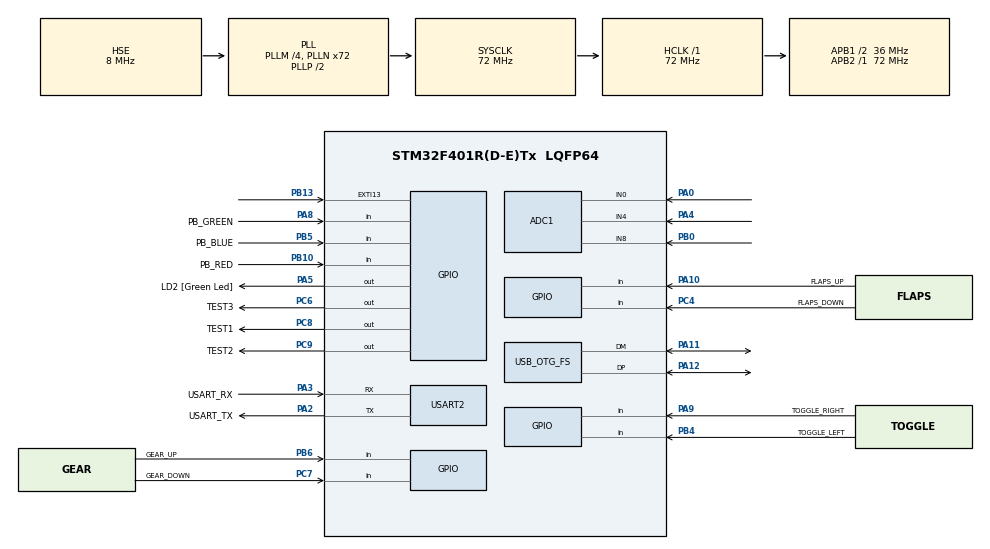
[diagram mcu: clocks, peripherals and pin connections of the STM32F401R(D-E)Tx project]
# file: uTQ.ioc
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ADC1.Channel-0\#ChannelRegularConversion=ADC_CHANNEL_0
ADC1.Channel-1\#ChannelRegularConversion=ADC_CHANNEL_8
ADC1.Channel-2\#ChannelRegularConversion=ADC_CHANNEL_4
ADC1.ClockPrescaler=ADC_CLOCK_SYNC_PCLK_DIV4
ADC1.EOCSelection=ADC_EOC_SEQ_CONV
ADC1.NbrOfConversion=3
ADC1.NbrOfConversionFlag=1
ADC1.Rank-0\#ChannelRegularConversion=1
ADC1.Rank-1\#ChannelRegularConversion=2
ADC1.Rank-2\#ChannelRegularConversion=3
ADC1.SamplingTime-0\#ChannelRegularConversion=ADC_SAMPLETIME_480CYCLES
ADC1.SamplingTime-1\#ChannelRegularConversion=ADC_SAMPLETIME_480CYCLES
ADC1.SamplingTime-2\#ChannelRegularConversion=ADC_SAMPLETIME_480CYCLES
ADC1.ScanConvMode=ENABLE
ADC1.master=1
Dma.ADC1.0.Direction=DMA_PERIPH_TO_MEMORY
Dma.ADC1.0.FIFOMode=DMA_FIFOMODE_DISABLE
Dma.ADC1.0.Instance=DMA2_Stream0
Dma.ADC1.0.MemDataAlignment=DMA_MDATAALIGN_HALFWORD
Dma.ADC1.0.MemInc=DMA_MINC_ENABLE
Dma.ADC1.0.Mode=DMA_NORMAL
Dma.ADC1.0.PeriphDataAlignment=DMA_PDATAALIGN_HALFWORD
Dma.ADC1.0.PeriphInc=DMA_PINC_DISABLE
Dma.ADC1.0.Priority=DMA_PRIORITY_LOW
Dma.Request0=ADC1
IWDG.Prescaler=IWDG_PRESCALER_16
IWDG.Reload=1999
Mcu.Family=STM32F4
Mcu.Name=STM32F401R(D-E)Tx
Mcu.Package=LQFP64
Mcu.UserConstants=CUSTOM_HID_EPIN_SIZE,64;CUSTOM_HID_EPOUT_SIZE,64
NVIC.DMA2_Stream0_IRQn=true\:10\:0\:true\:false\:true\:false\:true\:true
NVIC.OTG_FS_IRQn=true\:0\:0\:false\:false\:true\:false\:true\:true
NVIC.PriorityGroup=NVIC_PRIORITYGROUP_4
PA0-WKUP.Signal=ADCx_IN0
PA10.GPIO_Label=FLAPS_UP
PA10.GPIO_PuPd=GPIO_PULLUP
PA10.Signal=GPIO_Input
PA11.Mode=Device_Only
PA11.Signal=USB_OTG_FS_DM
PA12.Mode=Device_Only
PA12.Signal=USB_OTG_FS_DP
PA13.GPIO_Label=TMS
PA13.Mode=Serial_Wire
PA13.Signal=SYS_JTMS-SWDIO
PA14.GPIO_Label=TCK
PA14.Mode=Serial_Wire
PA14.Signal=SYS_JTCK-SWCLK
PA2.GPIO_Label=USART_TX
PA2.GPIO_Mode=GPIO_MODE_AF_PP
PA2.GPIO_PuPd=GPIO_NOPULL
PA2.GPIO_Speed=GPIO_SPEED_FREQ_LOW
PA2.Mode=Asynchronous
PA2.Signal=USART2_TX
PA3.GPIO_Label=USART_RX
PA3.GPIO_Mode=GPIO_MODE_AF_PP
PA3.GPIO_PuPd=GPIO_NOPULL
PA3.GPIO_Speed=GPIO_SPEED_FREQ_LOW
PA3.Mode=Asynchronous
PA3.Signal=USART2_RX
PA4.Signal=ADCx_IN4
PA5.GPIO_Label=LD2 [Green Led]
PA5.GPIO_Mode=GPIO_MODE_OUTPUT_PP
PA5.GPIO_PuPd=GPIO_NOPULL
PA5.GPIO_Speed=GPIO_SPEED_FREQ_LOW
PA5.Signal=GPIO_Output
PA8.GPIO_Label=PB_GREEN
PA8.GPIO_PuPd=GPIO_PULLUP
PA8.Signal=GPIO_Input
PA9.GPIO_Label=TOGGLE_RIGHT
PA9.GPIO_PuPd=GPIO_PULLUP
PA9.Signal=GPIO_Input
PB0.Signal=ADCx_IN8
PB10.GPIO_Label=PB_RED
PB10.GPIO_PuPd=GPIO_PULLUP
PB10.Signal=GPIO_Input
PB13.Signal=GPXTI13
PB3.GPIO_Label=SWO
PB3.Signal=SYS_JTDO-SWO
PB4.GPIO_Label=TOGGLE_LEFT
PB4.GPIO_PuPd=GPIO_PULLUP
PB4.Signal=GPIO_Input
PB5.GPIO_Label=PB_BLUE
PB5.GPIO_PuPd=GPIO_PULLUP
PB5.Signal=GPIO_Input
PB6.GPIO_Label=GEAR_UP
PB6.GPIO_PuPd=GPIO_PULLUP
PB6.Signal=GPIO_Input
PC14-OSC32_IN.Mode=LSE-External-Oscillator
PC14-OSC32_IN.Signal=RCC_OSC32_IN
PC15-OSC32_OUT.Mode=LSE-External-Oscillator
PC15-OSC32_OUT.Signal=RCC_OSC32_OUT
PC4.GPIO_Label=FLAPS_DOWN
PC4.GPIO_PuPd=GPIO_PULLUP
PC4.Signal=GPIO_Input
PC6.GPIO_Label=TEST3
PC6.Signal=GPIO_Output
PC7.GPIO_Label=GEAR_DOWN
PC7.GPIO_PuPd=GPIO_PULLUP
PC7.Signal=GPIO_Input
PC8.GPIO_Label=TEST1
PC8.Signal=GPIO_Output
PC9.GPIO_Label=TEST2
PC9.Signal=GPIO_Output
PH0\ -\ OSC_IN.Mode=HSE-External-Clock-Source
PH0\ -\ OSC_IN.Signal=RCC_OSC_IN
PH1\ -\ OSC_OUT.Mode=HSE-External-Clock-Source
PH1\ -\ OSC_OUT.Signal=RCC_OSC_OUT
ProjectManager.HeapSize=0x400
ProjectManager.StackSize=0x800
ProjectManager.TargetToolchain=CMake
RCC.48MHZClocksFreq_Value=48000000
RCC.AHBFreq_Value=72000000
RCC.APB1CLKDivider=RCC_HCLK_DIV2
RCC.APB1Freq_Value=36000000
RCC.APB1TimFreq_Value=72000000
RCC.APB2Freq_Value=72000000
RCC.APB2TimFreq_Value=72000000
RCC.CortexFreq_Value=72000000
RCC.HCLKFreq_Value=72000000
RCC.HSE_VALUE=8000000
RCC.HSI_VALUE=16000000
RCC.PLLM=4
RCC.PLLN=72
RCC.PLLQ=3
RCC.SYSCLKFreq_VALUE=72000000
RCC.SYSCLKSource=RCC_SYSCLKSOURCE_PLLCLK
RCC.VCOOutputFreq_Value=144000000
SH.ADCx_IN0.0=ADC1_IN0,IN0
SH.ADCx_IN4.0=ADC1_IN4,IN4
SH.ADCx_IN8.0=ADC1_IN8,IN8
TIM5.Prescaler=71
USART2.VirtualMode=VM_ASYNC
USB_DEVICE.CLASS_NAME_FS=CUSTOM_HID
USB_DEVICE.MANUFACTURER_STRING-CUSTOM_HID_FS=C2030
USB_DEVICE.PID_CUSTOMHID_FS=0x5715
USB_DEVICE.PRODUCT_STRING_CUSTOMHID_FS=micro TQ
USB_DEVICE.USBD_CUSTOMHID_OUTREPORT_BUF_SIZE-CUSTOM_HID_FS=64
USB_DEVICE.USBD_CUSTOM_HID_REPORT_DESC_SIZE-CUSTOM_HID_FS=96
USB_DEVICE.VID-CUSTOM_HID_FS=0x0483
USB_DEVICE.VirtualMode-CUSTOM_HID_FS=CustomHid
USB_DEVICE.VirtualModeFS=Custom_Hid_FS
USB_OTG_FS.VirtualMode=Device_Only
VP_IWDG_VS_IWDG.Mode=IWDG_Activate
VP_TIM5_VS_ClockSourceINT.Mode=Internal
VP_USB_DEVICE_VS_USB_DEVICE_CUSTOM_HID_FS.Mode=CUSTOM_HID_FS
board=NUCLEO-F401RE

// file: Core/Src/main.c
/* USER CODE BEGIN Header */
/**
  ******************************************************************************
  * @file           : main.c
  * @brief          : Main program body
  ******************************************************************************
  * @attention
  *
  * Copyright (c) 2022 STMicroelectronics.
  * All rights reserved.
  *
  * This software is licensed under terms that can be found in the LICENSE file
  * in the root directory of this software component.
  * If no LICENSE file comes with this software, it is provided AS-IS.
  *
  ******************************************************************************
  */
/* USER CODE END Header */
#include "main.h"
#include "usb_device.h"

/* USER CODE BEGIN Includes */
#include "main_loop_api.h"
#include "stdio_redirection.h"
/* USER CODE END Includes */

ADC_HandleTypeDef hadc1;
DMA_HandleTypeDef hdma_adc1;

IWDG_HandleTypeDef hiwdg;

TIM_HandleTypeDef htim5;

UART_HandleTypeDef huart2;

void SystemClock_Config(void);
static void MX_GPIO_Init(void);
static void MX_DMA_Init(void);
static void MX_USART2_UART_Init(void);
static void MX_TIM5_Init(void);
static void MX_ADC1_Init(void);
static void MX_IWDG_Init(void);

int main(void)
{

  /* USER CODE BEGIN 1 */

    pTimerHtim = &htim5;    /*htim5 used by Timer class*/
    pHadc = &hadc1;         /*pointer to hadc1, which will be used in main loop*/
    pIwdg = &hiwdg;         /* pointer to main loop watchdog */
  /* USER CODE END 1 */

  /* MCU Configuration--------------------------------------------------------*/

  /* Reset of all peripherals, Initializes the Flash interface and the Systick. */
  HAL_Init();

  /* Configure the system clock */
  SystemClock_Config();

  /* Initialize all configured peripherals */
  MX_GPIO_Init();
  MX_DMA_Init();
  MX_USART2_UART_Init();
  MX_TIM5_Init();
  MX_USB_DEVICE_Init();
  MX_ADC1_Init();
  MX_IWDG_Init();
  /* USER CODE BEGIN 2 */
  redirectStdio(&huart2);     /*redirect stdio to console UART*/
  /* USER CODE END 2 */

  /* Infinite loop */
  /* USER CODE BEGIN WHILE */
  mainLoop();   /*it never returns from this function*/

  while (1)
  {
    /* USER CODE END WHILE */

  }
}

void SystemClock_Config(void)
{
  RCC_OscInitTypeDef RCC_OscInitStruct = {0};
  RCC_ClkInitTypeDef RCC_ClkInitStruct = {0};

  /** Configure the main internal regulator output voltage
  */
  __HAL_RCC_PWR_CLK_ENABLE();
  __HAL_PWR_VOLTAGESCALING_CONFIG(PWR_REGULATOR_VOLTAGE_SCALE2);

  /** Initializes the RCC Oscillators according to the specified parameters
  * in the RCC_OscInitTypeDef structure.
  */
  RCC_OscInitStruct.OscillatorType = RCC_OSCILLATORTYPE_LSI|RCC_OSCILLATORTYPE_HSE;
  RCC_OscInitStruct.HSEState = RCC_HSE_BYPASS;
  RCC_OscInitStruct.LSIState = RCC_LSI_ON;
  RCC_OscInitStruct.PLL.PLLState = RCC_PLL_ON;
  RCC_OscInitStruct.PLL.PLLSource = RCC_PLLSOURCE_HSE;
  RCC_OscInitStruct.PLL.PLLM = 4;
  RCC_OscInitStruct.PLL.PLLN = 72;
  RCC_OscInitStruct.PLL.PLLP = RCC_PLLP_DIV2;
  RCC_OscInitStruct.PLL.PLLQ = 3;
  if (HAL_RCC_OscConfig(&RCC_OscInitStruct) != HAL_OK)
  {
    Error_Handler();
  }

  /** Initializes the CPU, AHB and APB buses clocks
  */
  RCC_ClkInitStruct.ClockType = RCC_CLOCKTYPE_HCLK|RCC_CLOCKTYPE_SYSCLK
                              |RCC_CLOCKTYPE_PCLK1|RCC_CLOCKTYPE_PCLK2;
  RCC_ClkInitStruct.SYSCLKSource = RCC_SYSCLKSOURCE_PLLCLK;
  RCC_ClkInitStruct.AHBCLKDivider = RCC_SYSCLK_DIV1;
  RCC_ClkInitStruct.APB1CLKDivider = RCC_HCLK_DIV2;
  RCC_ClkInitStruct.APB2CLKDivider = RCC_HCLK_DIV1;

  if (HAL_RCC_ClockConfig(&RCC_ClkInitStruct, FLASH_LATENCY_2) != HAL_OK)
  {
    Error_Handler();
  }
}

static void MX_ADC1_Init(void)
{

  ADC_ChannelConfTypeDef sConfig = {0};

  /** Configure the global features of the ADC (Clock, Resolution, Data Alignment and number of conversion)
  */
  hadc1.Instance = ADC1;
  hadc1.Init.ClockPrescaler = ADC_CLOCK_SYNC_PCLK_DIV4;
  hadc1.Init.Resolution = ADC_RESOLUTION_12B;
  hadc1.Init.ScanConvMode = ENABLE;
  hadc1.Init.ContinuousConvMode = DISABLE;
  hadc1.Init.DiscontinuousConvMode = DISABLE;
  hadc1.Init.ExternalTrigConvEdge = ADC_EXTERNALTRIGCONVEDGE_NONE;
  hadc1.Init.ExternalTrigConv = ADC_SOFTWARE_START;
  hadc1.Init.DataAlign = ADC_DATAALIGN_RIGHT;
  hadc1.Init.NbrOfConversion = 3;
  hadc1.Init.DMAContinuousRequests = DISABLE;
  hadc1.Init.EOCSelection = ADC_EOC_SEQ_CONV;
  if (HAL_ADC_Init(&hadc1) != HAL_OK)
  {
    Error_Handler();
  }

  /** Configure for the selected ADC regular channel its corresponding rank in the sequencer and its sample time.
  */
  sConfig.Channel = ADC_CHANNEL_0;
  sConfig.Rank = 1;
  sConfig.SamplingTime = ADC_SAMPLETIME_480CYCLES;
  if (HAL_ADC_ConfigChannel(&hadc1, &sConfig) != HAL_OK)
  {
    Error_Handler();
  }

  /** Configure for the selected ADC regular channel its corresponding rank in the sequencer and its sample time.
  */
  sConfig.Channel = ADC_CHANNEL_8;
  sConfig.Rank = 2;
  if (HAL_ADC_ConfigChannel(&hadc1, &sConfig) != HAL_OK)
  {
    Error_Handler();
  }

  /** Configure for the selected ADC regular channel its corresponding rank in the sequencer and its sample time.
  */
  sConfig.Channel = ADC_CHANNEL_4;
  sConfig.Rank = 3;
  if (HAL_ADC_ConfigChannel(&hadc1, &sConfig) != HAL_OK)
  {
    Error_Handler();
  }

}

static void MX_IWDG_Init(void)
{

  hiwdg.Instance = IWDG;
  hiwdg.Init.Prescaler = IWDG_PRESCALER_16;
  hiwdg.Init.Reload = 1999;
  if (HAL_IWDG_Init(&hiwdg) != HAL_OK)
  {
    Error_Handler();
  }

}

static void MX_TIM5_Init(void)
{

  TIM_ClockConfigTypeDef sClockSourceConfig = {0};
  TIM_MasterConfigTypeDef sMasterConfig = {0};

  htim5.Instance = TIM5;
  htim5.Init.Prescaler = 71;
  htim5.Init.CounterMode = TIM_COUNTERMODE_UP;
  htim5.Init.Period = 4294967295;
  htim5.Init.ClockDivision = TIM_CLOCKDIVISION_DIV1;
  htim5.Init.AutoReloadPreload = TIM_AUTORELOAD_PRELOAD_DISABLE;
  if (HAL_TIM_Base_Init(&htim5) != HAL_OK)
  {
    Error_Handler();
  }
  sClockSourceConfig.ClockSource = TIM_CLOCKSOURCE_INTERNAL;
  if (HAL_TIM_ConfigClockSource(&htim5, &sClockSourceConfig) != HAL_OK)
  {
    Error_Handler();
  }
  sMasterConfig.MasterOutputTrigger = TIM_TRGO_RESET;
  sMasterConfig.MasterSlaveMode = TIM_MASTERSLAVEMODE_DISABLE;
  if (HAL_TIMEx_MasterConfigSynchronization(&htim5, &sMasterConfig) != HAL_OK)
  {
    Error_Handler();
  }

}

static void MX_USART2_UART_Init(void)
{

  huart2.Instance = USART2;
  huart2.Init.BaudRate = 115200;
  huart2.Init.WordLength = UART_WORDLENGTH_8B;
  huart2.Init.StopBits = UART_STOPBITS_1;
  huart2.Init.Parity = UART_PARITY_NONE;
  huart2.Init.Mode = UART_MODE_TX_RX;
  huart2.Init.HwFlowCtl = UART_HWCONTROL_NONE;
  huart2.Init.OverSampling = UART_OVERSAMPLING_16;
  if (HAL_UART_Init(&huart2) != HAL_OK)
  {
    Error_Handler();
  }

}

static void MX_DMA_Init(void)
{

  /* DMA controller clock enable */
  __HAL_RCC_DMA2_CLK_ENABLE();

  /* DMA interrupt init */
  /* DMA2_Stream0_IRQn interrupt configuration */
  HAL_NVIC_SetPriority(DMA2_Stream0_IRQn, 10, 0);
  HAL_NVIC_EnableIRQ(DMA2_Stream0_IRQn);

}

static void MX_GPIO_Init(void)
{
  GPIO_InitTypeDef GPIO_InitStruct = {0};

  /* GPIO Ports Clock Enable */
  __HAL_RCC_GPIOC_CLK_ENABLE();
  __HAL_RCC_GPIOH_CLK_ENABLE();
  __HAL_RCC_GPIOA_CLK_ENABLE();
  __HAL_RCC_GPIOB_CLK_ENABLE();

  /*Configure GPIO pin Output Level */
  HAL_GPIO_WritePin(LD2_GPIO_Port, LD2_Pin, GPIO_PIN_RESET);

  /*Configure GPIO pin Output Level */
  HAL_GPIO_WritePin(GPIOC, TEST3_Pin|TEST1_Pin|TEST2_Pin, GPIO_PIN_RESET);

  /*Configure GPIO pin : LD2_Pin */
  GPIO_InitStruct.Pin = LD2_Pin;
  GPIO_InitStruct.Mode = GPIO_MODE_OUTPUT_PP;
  GPIO_InitStruct.Pull = GPIO_NOPULL;
  GPIO_InitStruct.Speed = GPIO_SPEED_FREQ_LOW;
  HAL_GPIO_Init(LD2_GPIO_Port, &GPIO_InitStruct);

  /*Configure GPIO pins : FLAPS_DOWN_Pin GEAR_DOWN_Pin */
  GPIO_InitStruct.Pin = FLAPS_DOWN_Pin|GEAR_DOWN_Pin;
  GPIO_InitStruct.Mode = GPIO_MODE_INPUT;
  GPIO_InitStruct.Pull = GPIO_PULLUP;
  HAL_GPIO_Init(GPIOC, &GPIO_InitStruct);

  /*Configure GPIO pins : PB_RED_Pin TOGGLE_LEFT_Pin PB_BLUE_Pin GEAR_UP_Pin */
  GPIO_InitStruct.Pin = PB_RED_Pin|TOGGLE_LEFT_Pin|PB_BLUE_Pin|GEAR_UP_Pin;
  GPIO_InitStruct.Mode = GPIO_MODE_INPUT;
  GPIO_InitStruct.Pull = GPIO_PULLUP;
  HAL_GPIO_Init(GPIOB, &GPIO_InitStruct);

  /*Configure GPIO pin : PB13 */
  GPIO_InitStruct.Pin = GPIO_PIN_13;
  GPIO_InitStruct.Mode = GPIO_MODE_IT_RISING;
  GPIO_InitStruct.Pull = GPIO_NOPULL;
  HAL_GPIO_Init(GPIOB, &GPIO_InitStruct);

  /*Configure GPIO pins : TEST3_Pin TEST1_Pin TEST2_Pin */
  GPIO_InitStruct.Pin = TEST3_Pin|TEST1_Pin|TEST2_Pin;
  GPIO_InitStruct.Mode = GPIO_MODE_OUTPUT_PP;
  GPIO_InitStruct.Pull = GPIO_NOPULL;
  GPIO_InitStruct.Speed = GPIO_SPEED_FREQ_LOW;
  HAL_GPIO_Init(GPIOC, &GPIO_InitStruct);

  /*Configure GPIO pins : PB_GREEN_Pin TOGGLE_RIGHT_Pin FLAPS_UP_Pin */
  GPIO_InitStruct.Pin = PB_GREEN_Pin|TOGGLE_RIGHT_Pin|FLAPS_UP_Pin;
  GPIO_InitStruct.Mode = GPIO_MODE_INPUT;
  GPIO_InitStruct.Pull = GPIO_PULLUP;
  HAL_GPIO_Init(GPIOA, &GPIO_InitStruct);

}

void Error_Handler(void)
{
  __disable_irq();
  while (1)
  {
  }
}
